# ioat91sam7s64 register map
Registers are 32-bit, access not given, no defined reset value unless marked. A register's access mark holds for its fields unless they carry their own. Addresses are absolute; registers are grouped by the start of their names; [hi:lo] are bit positions; {n}, {i} and the like mark numbered series; 'fields as' and 'values as' point back to an identical list.

## TC1
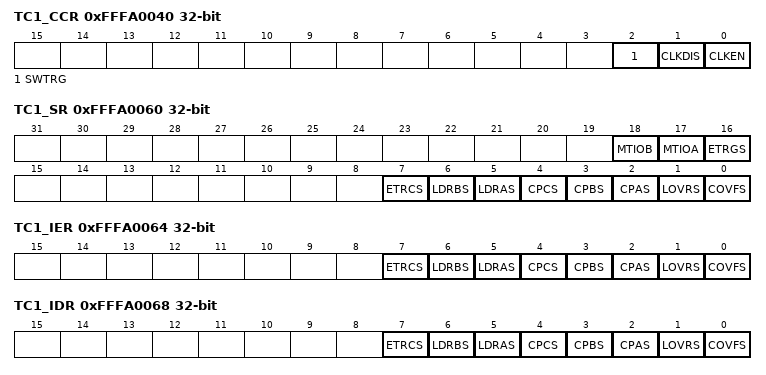
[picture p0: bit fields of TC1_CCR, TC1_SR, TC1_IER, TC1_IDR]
0xFFFA0040 TC1_CCR
  [2] SWTRG, [1] CLKDIS, [0] CLKEN
0xFFFA0044 TC1_CMR 40-bit
  [32:30] BSWTRG, [30:28] BEEVT, [28:26] BCPC, [26:24] BCPB, [24:22] ASWTRG, [22:20] AEEVT, [20:18] LDRB, [20:18] ACPC, [18:16] LDRA, [18:16] ACPA, [15] WAVE, [14] CPCTRG, [15:13] WAVESEL, [12] ENETRG, [10] ABETRG, [12:10] EEVT, [10:8] ETRGEDG, [10:8] EEVTEDG, [7] LDBDIS, [7] CPCDIS, [6] CPCSTOP, [6] LDBSTOP, [6:4] BURST, [3] CLKI, [3:0] CLKS
0xFFFA0050 TC1_CV
0xFFFA0054 TC1_RA
0xFFFA0058 TC1_RB
0xFFFA005C TC1_RC
0xFFFA0060 TC1_SR
  [18] MTIOB, [17] MTIOA, [16] ETRGS, [7] ETRCS, [6] LDRBS, [5] LDRAS, [4] CPCS, [3] CPBS, [2] CPAS, [1] LOVRS, [0] COVFS
0xFFFA0064 TC1_IER
  [7] ETRCS, [6] LDRBS, [5] LDRAS, [4] CPCS, [3] CPBS, [2] CPAS, [1] LOVRS, [0] COVFS
0xFFFA0068 TC1_IDR
  fields as TC1_IER
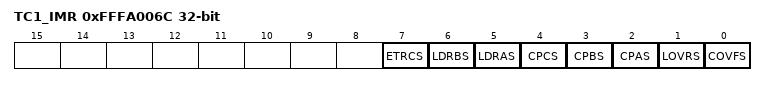
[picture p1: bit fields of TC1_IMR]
0xFFFA006C TC1_IMR
  fields as TC1_IER

## TC0
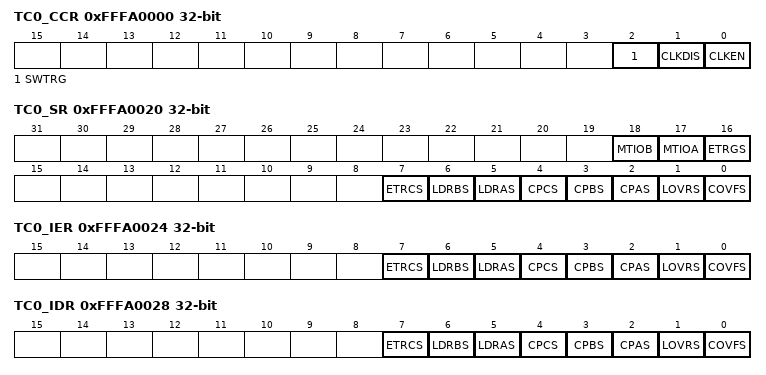
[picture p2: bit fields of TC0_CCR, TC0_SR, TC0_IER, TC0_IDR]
0xFFFA0000 TC0_CCR
  [2] SWTRG, [1] CLKDIS, [0] CLKEN
0xFFFA0004 TC0_CMR 40-bit
  [32:30] BSWTRG, [30:28] BEEVT, [28:26] BCPC, [26:24] BCPB, [24:22] ASWTRG, [22:20] AEEVT, [20:18] LDRB, [20:18] ACPC, [18:16] LDRA, [18:16] ACPA, [15] WAVE, [14] CPCTRG, [15:13] WAVESEL, [12] ENETRG, [10] ABETRG, [12:10] EEVT, [10:8] ETRGEDG, [10:8] EEVTEDG, [7] LDBDIS, [7] CPCDIS, [6] CPCSTOP, [6] LDBSTOP, [6:4] BURST, [3] CLKI, [3:0] CLKS
0xFFFA0010 TC0_CV
0xFFFA0014 TC0_RA
0xFFFA0018 TC0_RB
0xFFFA001C TC0_RC
0xFFFA0020 TC0_SR
  [18] MTIOB, [17] MTIOA, [16] ETRGS, [7] ETRCS, [6] LDRBS, [5] LDRAS, [4] CPCS, [3] CPBS, [2] CPAS, [1] LOVRS, [0] COVFS
0xFFFA0024 TC0_IER
  [7] ETRCS, [6] LDRBS, [5] LDRAS, [4] CPCS, [3] CPBS, [2] CPAS, [1] LOVRS, [0] COVFS
0xFFFA0028 TC0_IDR
  fields as TC0_IER
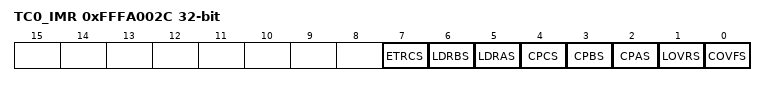
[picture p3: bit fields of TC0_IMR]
0xFFFA002C TC0_IMR
  fields as TC0_IER

## TCB
0xFFFA00C0 TCB_BCR
  [0] SYNC
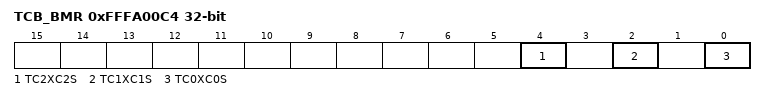
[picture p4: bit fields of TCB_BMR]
0xFFFA00C4 TCB_BMR
  [4] TC2XC2S, [2] TC1XC1S, [0] TC0XC0S

## CH3
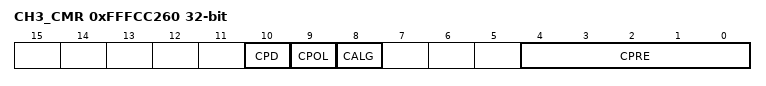
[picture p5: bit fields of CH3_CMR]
0xFFFCC260 CH3_CMR
  [10] CPD, [9] CPOL, [8] CALG, [4:0] CPRE
0xFFFCC264 CH3_CDTYR 40-bit
  [32:0] CDTY
0xFFFCC268 CH3_CPRDR 40-bit
  [32:0] CPRD
0xFFFCC26C CH3_CCNTR 40-bit
  [32:0] CCNT
0xFFFCC270 CH3_CUPDR 40-bit
  [32:0] CUPD
0xFFFCC274 CH3_Reserved

## CH2
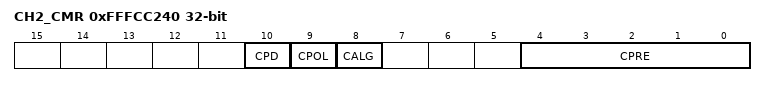
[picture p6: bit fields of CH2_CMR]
0xFFFCC240 CH2_CMR
  [10] CPD, [9] CPOL, [8] CALG, [4:0] CPRE
0xFFFCC244 CH2_CDTYR 40-bit
  [32:0] CDTY
0xFFFCC248 CH2_CPRDR 40-bit
  [32:0] CPRD
0xFFFCC24C CH2_CCNTR 40-bit
  [32:0] CCNT
0xFFFCC250 CH2_CUPDR 40-bit
  [32:0] CUPD
0xFFFCC254 CH2_Reserved

## CH1
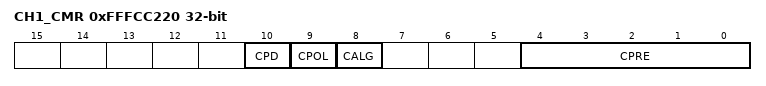
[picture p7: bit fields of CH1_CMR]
0xFFFCC220 CH1_CMR
  [10] CPD, [9] CPOL, [8] CALG, [4:0] CPRE
0xFFFCC224 CH1_CDTYR 40-bit
  [32:0] CDTY
0xFFFCC228 CH1_CPRDR 40-bit
  [32:0] CPRD
0xFFFCC22C CH1_CCNTR 40-bit
  [32:0] CCNT
0xFFFCC230 CH1_CUPDR 40-bit
  [32:0] CUPD
0xFFFCC234 CH1_Reserved

## CH0
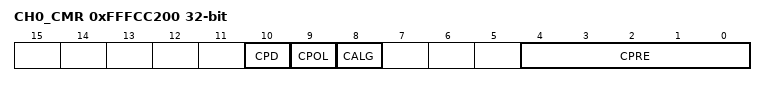
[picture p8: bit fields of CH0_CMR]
0xFFFCC200 CH0_CMR
  [10] CPD, [9] CPOL, [8] CALG, [4:0] CPRE
0xFFFCC204 CH0_CDTYR 40-bit
  [32:0] CDTY
0xFFFCC208 CH0_CPRDR 40-bit
  [32:0] CPRD
0xFFFCC20C CH0_CCNTR 40-bit
  [32:0] CCNT
0xFFFCC210 CH0_CUPDR 40-bit
  [32:0] CUPD
0xFFFCC214 CH0_Reserved

## PWMC
0xFFFCC000 PWMC_MR
  [28:24] PREB, [24:16] DIVB, [12:8] PREA, [8:0] DIVA
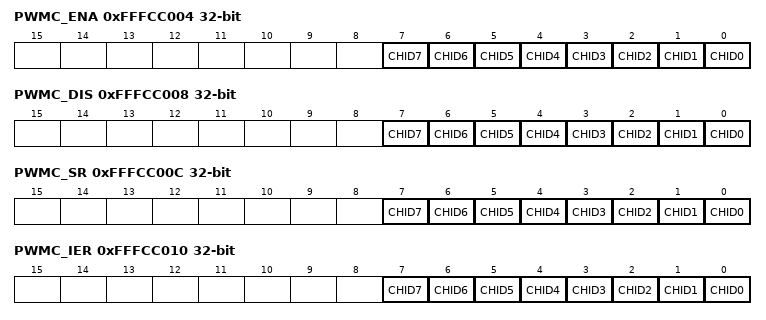
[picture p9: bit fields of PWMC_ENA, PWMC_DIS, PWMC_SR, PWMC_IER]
0xFFFCC004 PWMC_ENA
  [n] CHID{n} (n=0..7)
0xFFFCC008 PWMC_DIS
  [n] CHID{n} (n=0..7)
0xFFFCC00C PWMC_SR
  [n] CHID{n} (n=0..7)
0xFFFCC010 PWMC_IER
  [n] CHID{n} (n=0..7)
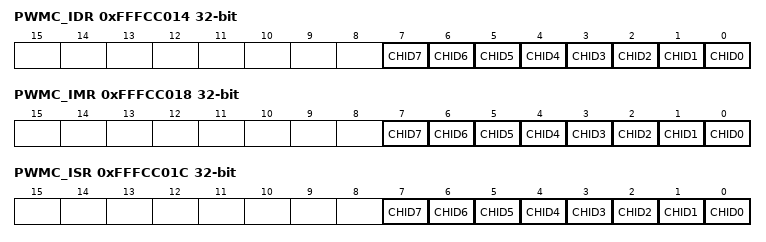
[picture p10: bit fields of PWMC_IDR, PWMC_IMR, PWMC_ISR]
0xFFFCC014 PWMC_IDR
  [n] CHID{n} (n=0..7)
0xFFFCC018 PWMC_IMR
  [n] CHID{n} (n=0..7)
0xFFFCC01C PWMC_ISR
  [n] CHID{n} (n=0..7)
0xFFFCC0FC PWMC_VR

## UDP
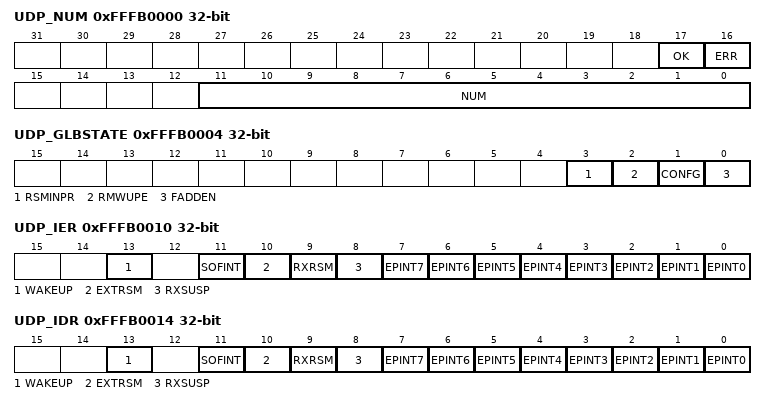
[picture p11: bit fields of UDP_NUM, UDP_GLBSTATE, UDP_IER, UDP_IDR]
0xFFFB0000 UDP_NUM
  [17] OK, [16] ERR, [11:0] NUM
0xFFFB0004 UDP_GLBSTATE
  [3] RSMINPR, [2] RMWUPE, [1] CONFG, [0] FADDEN
0xFFFB0008 UDP_FADDR
  [8] FEN, [8:0] FADD
0xFFFB0010 UDP_IER
  [13] WAKEUP, [11] SOFINT, [10] EXTRSM, [9] RXRSM, [8] RXSUSP, [n] EPINT{n} (n=0..7)
0xFFFB0014 UDP_IDR
  fields as UDP_IER
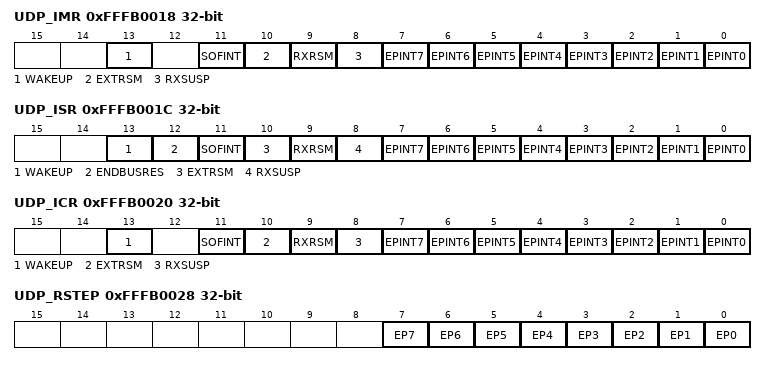
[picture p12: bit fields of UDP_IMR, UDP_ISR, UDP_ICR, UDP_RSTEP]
0xFFFB0018 UDP_IMR
  fields as UDP_IER
0xFFFB001C UDP_ISR
  [13] WAKEUP, [12] ENDBUSRES, [11] SOFINT, [10] EXTRSM, [9] RXRSM, [8] RXSUSP, [n] EPINT{n} (n=0..7)
0xFFFB0020 UDP_ICR
  fields as UDP_IER
0xFFFB0028 UDP_RSTEP
  [n] EP{n} (n=0..7)
0xFFFB0030 UDP_CSR
  [27:16] RXBYTECNT, [15] EPEDS, [11] DTGLE, [11:8] EPTYPE, [7] DIR, [6] BK1, [5] FORCESTALL, [4] TXPKTRDY, [3] ISOERROR, [2] RXSETUP, [1] BK0, [0] TXCOMP
0xFFFB0050 UDP_FDR

## SFR
0xFFFFFD60 SYSC_SYSC_VREG
  [0] PSTDBY
